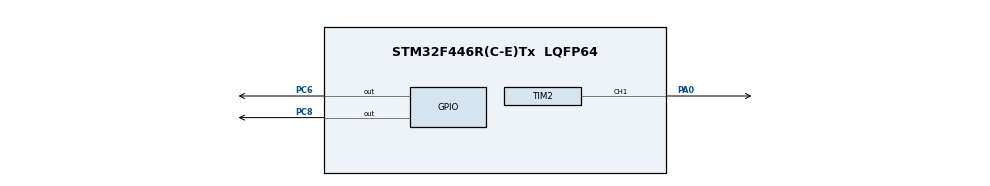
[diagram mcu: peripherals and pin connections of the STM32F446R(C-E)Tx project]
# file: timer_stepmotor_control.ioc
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Mcu.Family=STM32F4
Mcu.Name=STM32F446R(C-E)Tx
Mcu.Package=LQFP64
NVIC.PriorityGroup=NVIC_PRIORITYGROUP_4
NVIC.TIM2_IRQn=true\:0\:0\:false\:false\:true\:true\:true\:true
PA0-WKUP.Signal=S_TIM2_CH1_ETR
PC6.Signal=GPIO_Output
PC8.Signal=GPIO_Output
ProjectManager.HeapSize=0x200
ProjectManager.StackSize=0x400
ProjectManager.TargetToolchain=STM32CubeIDE
RCC.CortexFreq_Value=16000000
RCC.USBFreq_Value=96000000
RCC.VCOOutputFreq_Value=192000000
SH.S_TIM2_CH1_ETR.0=TIM2_CH1,Output Compare1 CH1
TIM2.Channel-Output\ Compare1\ CH1=TIM_CHANNEL_1
TIM2.OCMode_1=TIM_OCMODE_TOGGLE
TIM2.Prescaler=84-1
board=custom

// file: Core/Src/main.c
/* USER CODE BEGIN Header */
/**
  ******************************************************************************
  * @file           : main.c
  * @brief          : Main program body
  ******************************************************************************
  * @attention
  *
  * Copyright (c) 2026 STMicroelectronics.
  * All rights reserved.
  *
  * This software is licensed under terms that can be found in the LICENSE file
  * in the root directory of this software component.
  * If no LICENSE file comes with this software, it is provided AS-IS.
  *
  ******************************************************************************
  */
/* USER CODE END Header */
#include "main.h"

TIM_HandleTypeDef htim2;

/* USER CODE BEGIN PV */
#define EN_PORT   GPIOC
#define EN_PIN    GPIO_PIN_6

#define DIR_PORT  GPIOC
#define DIR_PIN   GPIO_PIN_8

static volatile uint32_t step_ccr_inc = 0;
/* USER CODE END PV */

void SystemClock_Config(void);
static void MX_GPIO_Init(void);
static void MX_TIM2_Init(void);

/* USER CODE BEGIN 0 */
static inline void tb_enable(uint8_t en) // en설정
{
  HAL_GPIO_WritePin(EN_PORT, EN_PIN, en ? GPIO_PIN_RESET : GPIO_PIN_SET);
}
static inline void tb_dir(uint8_t dir) // 방향설정
{
  HAL_GPIO_WritePin(DIR_PORT, DIR_PIN, dir ? GPIO_PIN_SET : GPIO_PIN_RESET);
}

static void set_step_freq(uint32_t step_hz)
{
  if (step_hz == 0)
  {
    HAL_TIM_OC_Stop_IT(&htim2, TIM_CHANNEL_1);
    return;
  }

  uint32_t tim_clk = HAL_RCC_GetPCLK1Freq();
  if ((RCC->CFGR & RCC_CFGR_PPRE1) != RCC_CFGR_PPRE1_DIV1) tim_clk *= 2;

  uint32_t psc = htim2.Init.Prescaler + 1;
  uint32_t tick_hz = tim_clk / psc;

  uint32_t inc = tick_hz / (2U * step_hz);
  if (inc < 10) inc = 10;

  step_ccr_inc = inc;

  // "지금 시점" 기준으로 첫 비교값을 예약
  uint32_t now = __HAL_TIM_GET_COUNTER(&htim2);
  __HAL_TIM_SET_COMPARE(&htim2, TIM_CHANNEL_1, now + step_ccr_inc);

  HAL_TIM_OC_Start_IT(&htim2, TIM_CHANNEL_1);
}

void user_test_run(void) // 모터 돌리기
{
  tb_dir(0);
  tb_enable(0);

  set_step_freq(1600);
  HAL_Delay(4000);

  // 정지
  set_step_freq(0);
  tb_enable(0);
}
/* USER CODE END 0 */

int main(void)
{

  /* MCU Configuration--------------------------------------------------------*/

  /* Reset of all peripherals, Initializes the Flash interface and the Systick. */
  HAL_Init();

  /* Configure the system clock */
  SystemClock_Config();

  /* Initialize all configured peripherals */
  MX_GPIO_Init();
  MX_TIM2_Init();
  /* USER CODE BEGIN 2 */
  user_test_run();
  /* USER CODE END 2 */

  /* Infinite loop */
  while (1)
  {

  }
}

void SystemClock_Config(void)
{
  RCC_OscInitTypeDef RCC_OscInitStruct = {0};
  RCC_ClkInitTypeDef RCC_ClkInitStruct = {0};

  /** Configure the main internal regulator output voltage
  */
  __HAL_RCC_PWR_CLK_ENABLE();
  __HAL_PWR_VOLTAGESCALING_CONFIG(PWR_REGULATOR_VOLTAGE_SCALE3);

  /** Initializes the RCC Oscillators according to the specified parameters
  * in the RCC_OscInitTypeDef structure.
  */
  RCC_OscInitStruct.OscillatorType = RCC_OSCILLATORTYPE_HSI;
  RCC_OscInitStruct.HSIState = RCC_HSI_ON;
  RCC_OscInitStruct.HSICalibrationValue = RCC_HSICALIBRATION_DEFAULT;
  RCC_OscInitStruct.PLL.PLLState = RCC_PLL_NONE;
  if (HAL_RCC_OscConfig(&RCC_OscInitStruct) != HAL_OK)
  {
    Error_Handler();
  }

  /** Initializes the CPU, AHB and APB buses clocks
  */
  RCC_ClkInitStruct.ClockType = RCC_CLOCKTYPE_HCLK|RCC_CLOCKTYPE_SYSCLK
                              |RCC_CLOCKTYPE_PCLK1|RCC_CLOCKTYPE_PCLK2;
  RCC_ClkInitStruct.SYSCLKSource = RCC_SYSCLKSOURCE_HSI;
  RCC_ClkInitStruct.AHBCLKDivider = RCC_SYSCLK_DIV1;
  RCC_ClkInitStruct.APB1CLKDivider = RCC_HCLK_DIV1;
  RCC_ClkInitStruct.APB2CLKDivider = RCC_HCLK_DIV1;

  if (HAL_RCC_ClockConfig(&RCC_ClkInitStruct, FLASH_LATENCY_0) != HAL_OK)
  {
    Error_Handler();
  }
}

static void MX_TIM2_Init(void)
{

  TIM_MasterConfigTypeDef sMasterConfig = {0};
  TIM_OC_InitTypeDef sConfigOC = {0};

  htim2.Instance = TIM2;
  htim2.Init.Prescaler = 84-1;
  htim2.Init.CounterMode = TIM_COUNTERMODE_UP;
  htim2.Init.Period = 4294967295;
  htim2.Init.ClockDivision = TIM_CLOCKDIVISION_DIV1;
  htim2.Init.AutoReloadPreload = TIM_AUTORELOAD_PRELOAD_DISABLE;
  if (HAL_TIM_OC_Init(&htim2) != HAL_OK)
  {
    Error_Handler();
  }
  sMasterConfig.MasterOutputTrigger = TIM_TRGO_RESET;
  sMasterConfig.MasterSlaveMode = TIM_MASTERSLAVEMODE_DISABLE;
  if (HAL_TIMEx_MasterConfigSynchronization(&htim2, &sMasterConfig) != HAL_OK)
  {
    Error_Handler();
  }
  sConfigOC.OCMode = TIM_OCMODE_TOGGLE;
  sConfigOC.Pulse = 0;
  sConfigOC.OCPolarity = TIM_OCPOLARITY_HIGH;
  sConfigOC.OCFastMode = TIM_OCFAST_DISABLE;
  if (HAL_TIM_OC_ConfigChannel(&htim2, &sConfigOC, TIM_CHANNEL_1) != HAL_OK)
  {
    Error_Handler();
  }
  HAL_TIM_MspPostInit(&htim2);

}

static void MX_GPIO_Init(void)
{
  GPIO_InitTypeDef GPIO_InitStruct = {0};

  /* GPIO Ports Clock Enable */
  __HAL_RCC_GPIOA_CLK_ENABLE();
  __HAL_RCC_GPIOC_CLK_ENABLE();

  /*Configure GPIO pin Output Level */
  HAL_GPIO_WritePin(GPIOC, GPIO_PIN_6|GPIO_PIN_8, GPIO_PIN_RESET);

  /*Configure GPIO pins : PC6 PC8 */
  GPIO_InitStruct.Pin = GPIO_PIN_6|GPIO_PIN_8;
  GPIO_InitStruct.Mode = GPIO_MODE_OUTPUT_PP;
  GPIO_InitStruct.Pull = GPIO_NOPULL;
  GPIO_InitStruct.Speed = GPIO_SPEED_FREQ_LOW;
  HAL_GPIO_Init(GPIOC, &GPIO_InitStruct);

}

/* USER CODE BEGIN 4 */
void HAL_TIM_OC_DelayElapsedCallback(TIM_HandleTypeDef *htim)
{
  if (htim->Instance == TIM2 && htim->Channel == HAL_TIM_ACTIVE_CHANNEL_1)
  {
    uint32_t ccr = __HAL_TIM_GET_COMPARE(htim, TIM_CHANNEL_1);
    __HAL_TIM_SET_COMPARE(htim, TIM_CHANNEL_1, ccr + step_ccr_inc);
  }
}
/* USER CODE END 4 */

void Error_Handler(void)
{
  __disable_irq();
  while (1)
  {
  }
}
